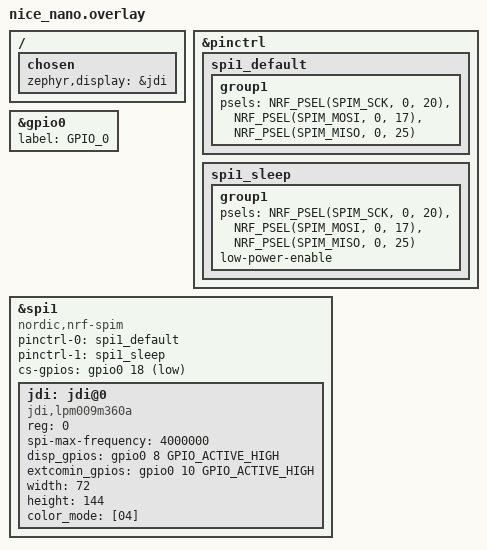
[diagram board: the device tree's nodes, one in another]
&pinctrl {
    spi1_default: spi1_default {
        group1 {
            psels = <NRF_PSEL(SPIM_SCK, 0, 20)>,
                <NRF_PSEL(SPIM_MOSI, 0, 17)>,
                <NRF_PSEL(SPIM_MISO, 0, 25)>;
        };
    };
    spi1_sleep: spi1_sleep {
        group1 {
            psels = <NRF_PSEL(SPIM_SCK, 0, 20)>,
                <NRF_PSEL(SPIM_MOSI, 0, 17)>,
                <NRF_PSEL(SPIM_MISO, 0, 25)>;
            low-power-enable;
        };
    };
};

&gpio0 {
	label = "GPIO_0";
	status = "okay";
};

&spi1 {
	status = "okay";
    compatible = "nordic,nrf-spim";
    pinctrl-0 = <&spi1_default>;
    pinctrl-1 = <&spi1_sleep>;
    pinctrl-names = "default", "sleep";
    cs-gpios = <&gpio0 18 GPIO_ACTIVE_LOW>;
	jdi: jdi@0 {
		compatible = "jdi,lpm009m360a";
		reg = <0>;
		status = "okay";
		spi-max-frequency = <4000000>;
		disp_gpios = <&gpio0 8 GPIO_ACTIVE_HIGH>;
		extcomin_gpios = <&gpio0 10 GPIO_ACTIVE_HIGH>;
		width = <72>;
		height = <144>;
        color_mode = [04];
	};
};

/{
	chosen {
		zephyr,display = &jdi;
	};
};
